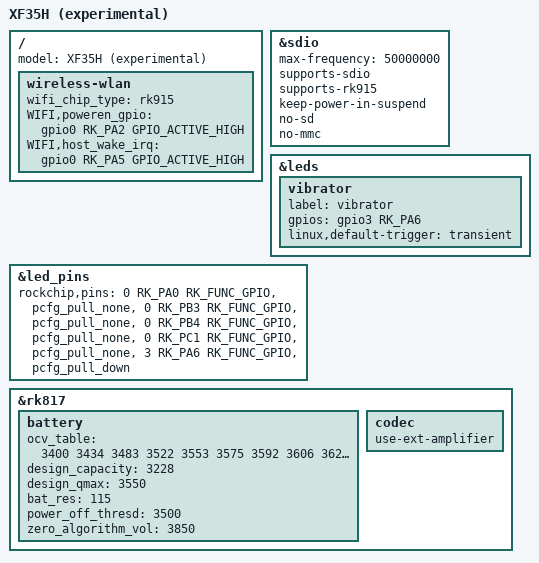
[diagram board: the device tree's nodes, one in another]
// SPDX-License-Identifier: (GPL-2.0+ OR MIT)
/*
 * EXPERIMENTAL - not tested on hardware by andr36oid. Keep a copy of the
 * files you replace so you can go back.
 *
 * XF35H (eMMC model): EE clone K36 wiring, 640x480 Panel 8, RK915 SDIO
 * Wi-Fi, rumble motor on GPIO3_A6, speaker through an external
 * amplifier, 3228 mAh.
 * Values from the stock DTB dumped from the console.
 */

/dts-v1/;
#include "rk3326-r36s-clone-ee-k36.dtsi"
#include "rk3326-r36s-clone-panel8.dtsi"

/ {
	model = "XF35H (experimental)";
};

/*
 * RK915 SDIO Wi-Fi instead of a second card slot. Power enable GPIO0_A2
 * (active high), out-of-band interrupt GPIO0_A5 (the R36 Ultra uses
 * GPIO0_A1), as in the stock DTB. Needs the RK915 driver (night/rk915),
 * which reads supports-rk915 and wifi_chip_type "rk915"; kernels without
 * it ignore both. (Stock sets "supports-rk912"; the 4.19 driver uses
 * "supports-rk915".)
 */
/ {
	wireless-wlan {
		wifi_chip_type = "rk915";
		WIFI,poweren_gpio = <&gpio0 RK_PA2 GPIO_ACTIVE_HIGH>;
		WIFI,host_wake_irq = <&gpio0 RK_PA5 GPIO_ACTIVE_HIGH>;
	};
};

&sdio {
	/delete-property/ supports-sd;
	/delete-property/ cd-gpios;
	/delete-property/ card-detect-delay;
	/delete-property/ cap-mmc-highspeed;
	/delete-property/ sd-uhs-sdr12;
	/delete-property/ sd-uhs-sdr25;
	/delete-property/ sd-uhs-sdr50;
	/delete-property/ sd-uhs-sdr104;
	/delete-property/ vmmc-supply;
	/delete-property/ vqmmc-supply;
	max-frequency = <50000000>;
	supports-sdio;
	supports-rk915;
	keep-power-in-suspend;
	no-sd;
	no-mmc;
};

/* rumble motor ("moto-gpio" in the stock DTB, active high) */
&leds {
	vibrator {
		label = "vibrator";
		gpios = <&gpio3 RK_PA6 GPIO_ACTIVE_HIGH>;
		linux,default-trigger = "transient";
	};
};

&led_pins {
	rockchip,pins =
		<0 RK_PA0 RK_FUNC_GPIO &pcfg_pull_none>,
		<0 RK_PB3 RK_FUNC_GPIO &pcfg_pull_none>,
		<0 RK_PB4 RK_FUNC_GPIO &pcfg_pull_none>,
		<0 RK_PC1 RK_FUNC_GPIO &pcfg_pull_none>,
		<3 RK_PA6 RK_FUNC_GPIO &pcfg_pull_down>;
};

&rk817 {
	battery {
		/*
		 * Stock values, from the stock DTB dumped from the XF35H (the
		 * XF40H has the same).
		 */
		ocv_table = <3400 3434 3483 3522 3553 3575 3592
			3606 3622 3642 3674 3720 3764 3809
			3849 3883 3919 3975 4018 4071 4181>;
		design_capacity = <3228>;
		design_qmax = <3550>;
		bat_res = <115>;
		power_off_thresd = <3500>;
		zero_algorithm_vol = <3850>;
	};
};

/* the speaker runs through an external amplifier (stock "use-ext-amplifier") */
&rk817 {
	codec {
		use-ext-amplifier;
	};
};
